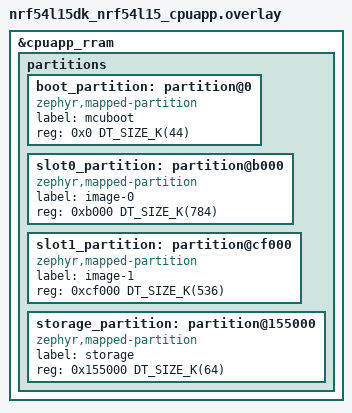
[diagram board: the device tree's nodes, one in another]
/*
 * Copyright (c) 2025 Nordic Semiconductor ASA
 *
 * SPDX-License-Identifier: LicenseRef-Nordic-5-Clause
 */

/delete-node/ &boot_partition;
/delete-node/ &slot0_partition;
/delete-node/ &slot1_partition;
/delete-node/ &storage_partition;

&cpuapp_rram {
	partitions {
		ranges;
		#address-cells = <1>;
		#size-cells = <1>;

		boot_partition: partition@0 {
			compatible = "zephyr,mapped-partition";
			label = "mcuboot";
			reg = <0x0 DT_SIZE_K(44)>;
		};

		slot0_partition: partition@b000 {
			compatible = "zephyr,mapped-partition";
			label = "image-0";
			reg = <0xb000 DT_SIZE_K(784)>;
		};

		slot1_partition: partition@cf000 {
			compatible = "zephyr,mapped-partition";
			label = "image-1";
			reg = <0xcf000 DT_SIZE_K(536)>;
		};

		storage_partition: partition@155000 {
			compatible = "zephyr,mapped-partition";
			label = "storage";
			reg = <0x155000 DT_SIZE_K(64)>;
		};
	};
};
